AUTOSAR XML (schema 4-2-1)
package /ComponentTypes
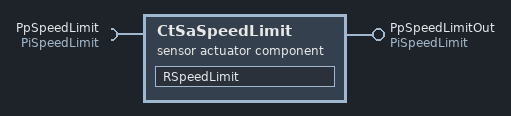
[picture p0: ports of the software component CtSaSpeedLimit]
  sensor actuator sw component type CtSaSpeedLimit
    provide port PpSpeedLimitOut: nonqueued-sender-com-spec{data-element=DeSpeedLimit, init-value=constant-reference=CSpeedLimit}, provided-interface=PiSpeedLimit
    require port PpSpeedLimit: nonqueued-receiver-com-spec{data-element=DeSpeedLimit, filter=data-filter-type=ALWAYS}, required-interface=PiSpeedLimit
    behavior CtSaSpeedLimit_InternalBehavior: data-type-mapping=ApMappingSet
      data received event DRT_RSpeedLimit_PpSpeedLimit_DeSpeedLimit: start-on-event=RSpeedLimit, data=PpSpeedLimit.DeSpeedLimit
      runnable RSpeedLimit
        data-receive-point-by-arguments:
          access REC_PpSpeedLimit_DeSpeedLimit: accessed-variable=PpSpeedLimit.DeSpeedLimit
        data-send-points:
          access SEND_PpSpeedLimitOut_DeSpeedLimit: accessed-variable=PpSpeedLimitOut.DeSpeedLimit
  swc implementation CtSaSpeedLimit_Implementation: behavior=CtSaSpeedLimit_InternalBehavior
    code-descriptors:
      code Default: artifact-descriptors=autosar-engineering-object={short-label=Default, category=SWSRC}
